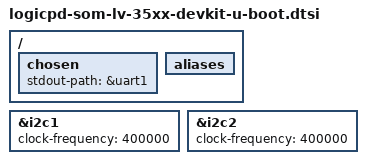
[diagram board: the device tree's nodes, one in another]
// SPDX-License-Identifier: GPL-2.0+
/*
 * Copyright (C) 2017
 * Logic PD - http://www.logicpd.com
 */

#include "omap3-u-boot.dtsi"

/ {
	chosen {
		stdout-path = &uart1;
	};

	aliases {
		/delete-property/ serial1;
		/delete-property/ serial2;
	};
};

&i2c1 {
	clock-frequency = <400000>;
};

&i2c2 {
	clock-frequency = <400000>;
};

/delete-node/ &uart2;
/delete-node/ &uart3;
/delete-node/ &mmc2;
/delete-node/ &mmc3;

